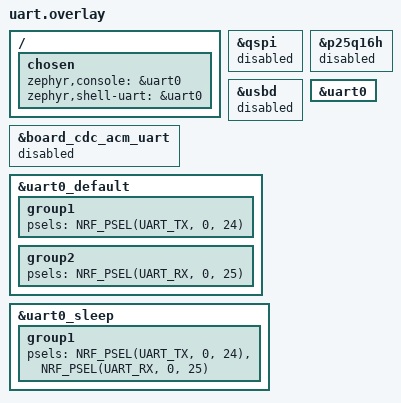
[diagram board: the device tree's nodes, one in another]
/* The nRF52840 platform has UART but lacks XIAO's QSPI and USB controllers. */
&qspi { status = "disabled"; };
&p25q16h { status = "disabled"; };
&usbd { status = "disabled"; };
&board_cdc_acm_uart { status = "disabled"; };

&uart0 { status = "okay"; };

/* Leave the MeKaBu matrix and module pins intact. These pins are QSPI on the XIAO. */
&uart0_default {
    group1 { psels = <NRF_PSEL(UART_TX, 0, 24)>; };
    group2 { psels = <NRF_PSEL(UART_RX, 0, 25)>; };
};

&uart0_sleep {
    group1 { psels = <NRF_PSEL(UART_TX, 0, 24)>, <NRF_PSEL(UART_RX, 0, 25)>; };
};

/ {
    chosen {
        zephyr,console = &uart0;
        zephyr,shell-uart = &uart0;
    };
};
